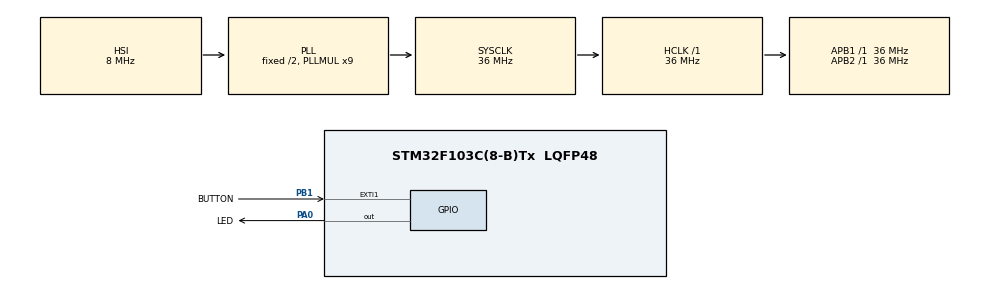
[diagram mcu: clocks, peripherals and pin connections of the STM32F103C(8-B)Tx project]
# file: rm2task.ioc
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Mcu.Family=STM32F1
Mcu.Name=STM32F103C(8-B)Tx
Mcu.Package=LQFP48
NVIC.EXTI1_IRQn=true\:1\:0\:true\:false\:true\:true\:true\:true
NVIC.PriorityGroup=NVIC_PRIORITYGROUP_4
NVIC.TIM2_IRQn=true\:2\:0\:true\:false\:true\:true\:true\:true
NVIC.TIM3_IRQn=true\:3\:0\:true\:false\:true\:true\:true\:true
PA0-WKUP.GPIO_Label=LED
PA0-WKUP.Signal=GPIO_Output
PA13.Mode=Serial_Wire
PA13.Signal=SYS_JTMS-SWDIO
PA14.Mode=Serial_Wire
PA14.Signal=SYS_JTCK-SWCLK
PB1.GPIO_Label=BUTTON
PB1.GPIO_ModeDefaultEXTI=GPIO_MODE_IT_FALLING
PB1.GPIO_PuPd=GPIO_PULLUP
PB1.Signal=GPXTI1
ProjectManager.HeapSize=0x200
ProjectManager.StackSize=0x400
ProjectManager.TargetToolchain=CMake
RCC.AHBFreq_Value=36000000
RCC.APB1Freq_Value=36000000
RCC.APB1TimFreq_Value=36000000
RCC.APB2Freq_Value=36000000
RCC.APB2TimFreq_Value=36000000
RCC.HCLKFreq_Value=36000000
RCC.PLLMUL=RCC_PLL_MUL9
RCC.SYSCLKFreq_VALUE=36000000
RCC.SYSCLKSource=RCC_SYSCLKSOURCE_PLLCLK
RCC.USBFreq_Value=36000000
TIM2.AutoReloadPreload=TIM_AUTORELOAD_PRELOAD_ENABLE
TIM2.Period=3599
TIM2.Prescaler=199
TIM3.AutoReloadPreload=TIM_AUTORELOAD_PRELOAD_ENABLE
TIM3.Period=3599
TIM3.Prescaler=9999
VP_TIM2_VS_ClockSourceINT.Mode=Internal
VP_TIM3_VS_ClockSourceINT.Mode=Internal
board=custom

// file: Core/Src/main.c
/* USER CODE BEGIN Header */
/**
  ******************************************************************************
  * @file           : main.c
  * @brief          : Main program body
  ******************************************************************************
  * @attention
  *
  * Copyright (c) 2026 STMicroelectronics.
  * All rights reserved.
  *
  * This software is licensed under terms that can be found in the LICENSE file
  * in the root directory of this software component.
  * If no LICENSE file comes with this software, it is provided AS-IS.
  *
  ******************************************************************************
  */
/* USER CODE END Header */
#include "main.h"

TIM_HandleTypeDef htim2;
TIM_HandleTypeDef htim3;

/* USER CODE BEGIN PV */
volatile uint8_t button_xiaodou=0;
uint32_t start_time=0;
uint8_t count=0;
uint32_t long_a=0;//后缀为a的都是标志值，用0和1代指当前状态
/* USER CODE END PV */

void SystemClock_Config(void);
static void MX_GPIO_Init(void);
static void MX_TIM2_Init(void);
static void MX_TIM3_Init(void);

int main(void)
{

  /* MCU Configuration--------------------------------------------------------*/

  /* Reset of all peripherals, Initializes the Flash interface and the Systick. */
  HAL_Init();

  /* Configure the system clock */
  SystemClock_Config();

  /* Initialize all configured peripherals */
  MX_GPIO_Init();
  MX_TIM2_Init();
  MX_TIM3_Init();

  /* Infinite loop */
  while (1)
  {

    /* USER CODE BEGIN 3 */
    if (count==1)
    {
      if (HAL_GPIO_ReadPin(GPIOB,GPIO_PIN_1)==GPIO_PIN_SET)
      {HAL_GPIO_TogglePin(GPIOA,GPIO_PIN_0); count=0;}
      if (HAL_GetTick()-start_time>=1000 && HAL_GPIO_ReadPin(GPIOB,GPIO_PIN_1)==GPIO_PIN_RESET)
      {
        long_a++;
        count=0;
      }
    }
    if(long_a%2==1)
    {
      HAL_GPIO_TogglePin(GPIOA,GPIO_PIN_0);
      HAL_Delay(100);
    }

  }
  /* USER CODE END 3 */
}

void SystemClock_Config(void)
{
  RCC_OscInitTypeDef RCC_OscInitStruct = {0};
  RCC_ClkInitTypeDef RCC_ClkInitStruct = {0};

  /** Initializes the RCC Oscillators according to the specified parameters
  * in the RCC_OscInitTypeDef structure.
  */
  RCC_OscInitStruct.OscillatorType = RCC_OSCILLATORTYPE_HSI;
  RCC_OscInitStruct.HSIState = RCC_HSI_ON;
  RCC_OscInitStruct.HSICalibrationValue = RCC_HSICALIBRATION_DEFAULT;
  RCC_OscInitStruct.PLL.PLLState = RCC_PLL_ON;
  RCC_OscInitStruct.PLL.PLLSource = RCC_PLLSOURCE_HSI_DIV2;
  RCC_OscInitStruct.PLL.PLLMUL = RCC_PLL_MUL9;
  if (HAL_RCC_OscConfig(&RCC_OscInitStruct) != HAL_OK)
  {
    Error_Handler();
  }

  /** Initializes the CPU, AHB and APB buses clocks
  */
  RCC_ClkInitStruct.ClockType = RCC_CLOCKTYPE_HCLK|RCC_CLOCKTYPE_SYSCLK
                              |RCC_CLOCKTYPE_PCLK1|RCC_CLOCKTYPE_PCLK2;
  RCC_ClkInitStruct.SYSCLKSource = RCC_SYSCLKSOURCE_PLLCLK;
  RCC_ClkInitStruct.AHBCLKDivider = RCC_SYSCLK_DIV1;
  RCC_ClkInitStruct.APB1CLKDivider = RCC_HCLK_DIV1;
  RCC_ClkInitStruct.APB2CLKDivider = RCC_HCLK_DIV1;

  if (HAL_RCC_ClockConfig(&RCC_ClkInitStruct, FLASH_LATENCY_1) != HAL_OK)
  {
    Error_Handler();
  }
}

static void MX_TIM2_Init(void)
{

  TIM_ClockConfigTypeDef sClockSourceConfig = {0};
  TIM_MasterConfigTypeDef sMasterConfig = {0};

  htim2.Instance = TIM2;
  htim2.Init.Prescaler = 199;
  htim2.Init.CounterMode = TIM_COUNTERMODE_UP;
  htim2.Init.Period = 3599;
  htim2.Init.ClockDivision = TIM_CLOCKDIVISION_DIV1;
  htim2.Init.AutoReloadPreload = TIM_AUTORELOAD_PRELOAD_ENABLE;
  if (HAL_TIM_Base_Init(&htim2) != HAL_OK)
  {
    Error_Handler();
  }
  sClockSourceConfig.ClockSource = TIM_CLOCKSOURCE_INTERNAL;
  if (HAL_TIM_ConfigClockSource(&htim2, &sClockSourceConfig) != HAL_OK)
  {
    Error_Handler();
  }
  sMasterConfig.MasterOutputTrigger = TIM_TRGO_RESET;
  sMasterConfig.MasterSlaveMode = TIM_MASTERSLAVEMODE_DISABLE;
  if (HAL_TIMEx_MasterConfigSynchronization(&htim2, &sMasterConfig) != HAL_OK)
  {
    Error_Handler();
  }

}

static void MX_TIM3_Init(void)
{

  TIM_ClockConfigTypeDef sClockSourceConfig = {0};
  TIM_MasterConfigTypeDef sMasterConfig = {0};

  htim3.Instance = TIM3;
  htim3.Init.Prescaler = 9999;
  htim3.Init.CounterMode = TIM_COUNTERMODE_UP;
  htim3.Init.Period = 3599;
  htim3.Init.ClockDivision = TIM_CLOCKDIVISION_DIV1;
  htim3.Init.AutoReloadPreload = TIM_AUTORELOAD_PRELOAD_ENABLE;
  if (HAL_TIM_Base_Init(&htim3) != HAL_OK)
  {
    Error_Handler();
  }
  sClockSourceConfig.ClockSource = TIM_CLOCKSOURCE_INTERNAL;
  if (HAL_TIM_ConfigClockSource(&htim3, &sClockSourceConfig) != HAL_OK)
  {
    Error_Handler();
  }
  sMasterConfig.MasterOutputTrigger = TIM_TRGO_RESET;
  sMasterConfig.MasterSlaveMode = TIM_MASTERSLAVEMODE_DISABLE;
  if (HAL_TIMEx_MasterConfigSynchronization(&htim3, &sMasterConfig) != HAL_OK)
  {
    Error_Handler();
  }

}

static void MX_GPIO_Init(void)
{
  GPIO_InitTypeDef GPIO_InitStruct = {0};

  /* GPIO Ports Clock Enable */
  __HAL_RCC_GPIOA_CLK_ENABLE();
  __HAL_RCC_GPIOB_CLK_ENABLE();

  /*Configure GPIO pin Output Level */
  HAL_GPIO_WritePin(LED_GPIO_Port, LED_Pin, GPIO_PIN_RESET);

  /*Configure GPIO pin : LED_Pin */
  GPIO_InitStruct.Pin = LED_Pin;
  GPIO_InitStruct.Mode = GPIO_MODE_OUTPUT_PP;
  GPIO_InitStruct.Pull = GPIO_NOPULL;
  GPIO_InitStruct.Speed = GPIO_SPEED_FREQ_LOW;
  HAL_GPIO_Init(LED_GPIO_Port, &GPIO_InitStruct);

  /*Configure GPIO pin : BUTTON_Pin */
  GPIO_InitStruct.Pin = BUTTON_Pin;
  GPIO_InitStruct.Mode = GPIO_MODE_IT_FALLING;
  GPIO_InitStruct.Pull = GPIO_PULLUP;
  HAL_GPIO_Init(BUTTON_GPIO_Port, &GPIO_InitStruct);

  /* EXTI interrupt init*/
  HAL_NVIC_SetPriority(EXTI1_IRQn, 1, 0);
  HAL_NVIC_EnableIRQ(EXTI1_IRQn);

}

/* USER CODE BEGIN 4 */
void HAL_GPIO_EXTI_Callback(uint16_t GPIO_Pin)//其中有第一次作业的消抖内容
{
  if (GPIO_Pin==BUTTON_Pin)
  {
    if (button_xiaodou==0)
    {
      button_xiaodou=1;
      start_time=HAL_GetTick();
      if(HAL_TIM_Base_Start_IT(&htim2)!=HAL_OK)
        Error_Handler();
    }

  }
}
void HAL_TIM_PeriodElapsedCallback(TIM_HandleTypeDef *htim)
{
  if (htim->Instance==TIM2) {
    HAL_TIM_Base_Stop_IT(&htim2);

    if (HAL_GPIO_ReadPin(GPIOB,GPIO_PIN_1)==GPIO_PIN_RESET)
    {
        count=1;
    }
    __HAL_TIM_SET_COUNTER(&htim2,0);
    button_xiaodou=0;
  }
}
/* USER CODE END 4 */

void Error_Handler(void)
{
  __disable_irq();
  while (1)
  {
  }
}
